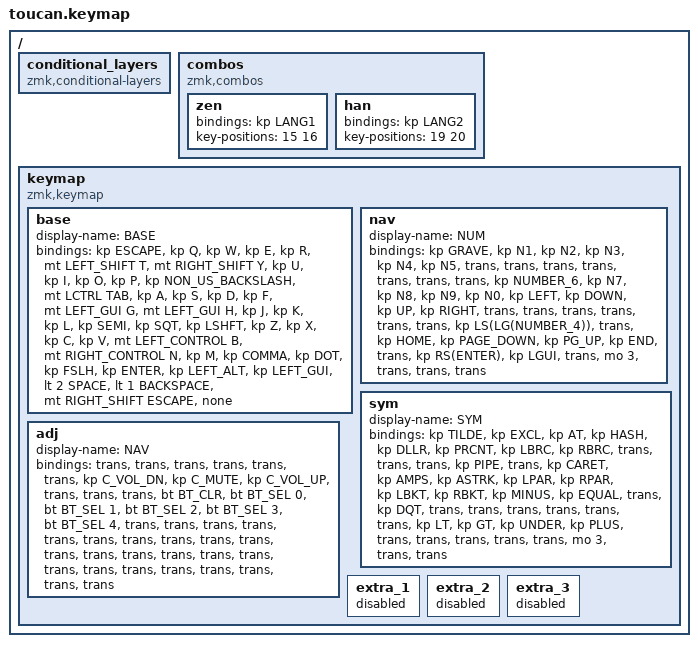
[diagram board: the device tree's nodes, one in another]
#include <behaviors.dtsi>
#include <dt-bindings/zmk/bt.h>
#include <dt-bindings/zmk/keys.h>

#define BASE 0
#define NAV  1
#define SYM  2
#define ADJ  3

/ {
    conditional_layers { compatible = "zmk,conditional-layers"; };

    combos {
        compatible = "zmk,combos";

        zen {
            bindings = <&kp LANG1>;
            key-positions = <15 16>;
        };

        han {
            bindings = <&kp LANG2>;
            key-positions = <19 20>;
        };
    };

    keymap {
        compatible = "zmk,keymap";

        base {
            display-name = "BASE";
            bindings = <
&kp ESCAPE  &kp Q  &kp W  &kp E  &kp R  &mt LEFT_SHIFT T  &mt RIGHT_SHIFT Y  &kp U  &kp I  &kp O  &kp P  &kp NON_US_BACKSLASH  &mt LCTRL TAB  &kp A  &kp S  &kp D  &kp F  &mt LEFT_GUI G  &mt LEFT_GUI H  &kp J  &kp K  &kp L  &kp SEMI  &kp SQT  &kp LSHFT  &kp Z  &kp X  &kp C  &kp V  &mt LEFT_CONTROL B  &mt RIGHT_CONTROL N  &kp M  &kp COMMA  &kp DOT  &kp FSLH  &kp ENTER  &kp LEFT_ALT  &kp LEFT_GUI  &lt 2 SPACE  &lt 1 BACKSPACE  &mt RIGHT_SHIFT ESCAPE  &none
            >;
        };

        nav {
            display-name = "NUM";
            bindings = <
&kp GRAVE  &kp N1  &kp N2  &kp N3  &kp N4  &kp N5  &trans  &trans  &trans  &trans  &trans  &trans  &trans  &kp NUMBER_6  &kp N7  &kp N8  &kp N9  &kp N0  &kp LEFT  &kp DOWN  &kp UP  &kp RIGHT  &trans  &trans  &trans  &trans  &trans  &trans  &kp LS(LG(NUMBER_4))  &trans  &kp HOME  &kp PAGE_DOWN  &kp PG_UP  &kp END  &trans  &kp RS(ENTER)  &kp LGUI  &trans  &mo 3  &trans  &trans  &trans
            >;
        };

        sym {
            display-name = "SYM";
            bindings = <
&kp TILDE  &kp EXCL  &kp AT  &kp HASH  &kp DLLR  &kp PRCNT  &kp LBRC  &kp RBRC  &trans  &trans  &trans  &kp PIPE  &trans  &kp CARET  &kp AMPS  &kp ASTRK  &kp LPAR  &kp RPAR  &kp LBKT  &kp RBKT  &kp MINUS  &kp EQUAL  &trans  &kp DQT  &trans  &trans  &trans  &trans  &trans  &trans  &kp LT  &kp GT  &kp UNDER  &kp PLUS  &trans  &trans  &trans  &trans  &trans  &mo 3  &trans  &trans
            >;
        };

        adj {
            display-name = "NAV";
            bindings = <
&trans  &trans  &trans  &trans  &trans  &trans  &kp C_VOL_DN  &kp C_MUTE  &kp C_VOL_UP  &trans  &trans  &trans  &bt BT_CLR  &bt BT_SEL 0  &bt BT_SEL 1  &bt BT_SEL 2  &bt BT_SEL 3  &bt BT_SEL 4  &trans  &trans  &trans  &trans  &trans  &trans  &trans  &trans  &trans  &trans  &trans  &trans  &trans  &trans  &trans  &trans  &trans  &trans  &trans  &trans  &trans  &trans  &trans  &trans
            >;
        };

        extra_1 { status = "reserved"; };

        extra_2 { status = "reserved"; };

        extra_3 { status = "reserved"; };
    };
};
